# ML630Q466 register map
Vendor: LAPIS Semiconductor Co.,Ltd.; File version: 1.00
CPU: CM0PLUS r0p1, little endian, no MPU, no FPU, 2 interrupt priority bits
Registers are 32-bit, read-write, no defined reset value unless marked. A register's access mark holds for its fields unless they carry their own. Offsets are from the block's base; [hi:lo] are bit positions; {n}, {i} and the like mark numbered series.

## UART0
Base 0x41001000
0x00 UA0BUF ro — UART0 receive buffer
  [7:0] U0B
0x04 UA0CON — UART0 control register
  [7:0] U1B
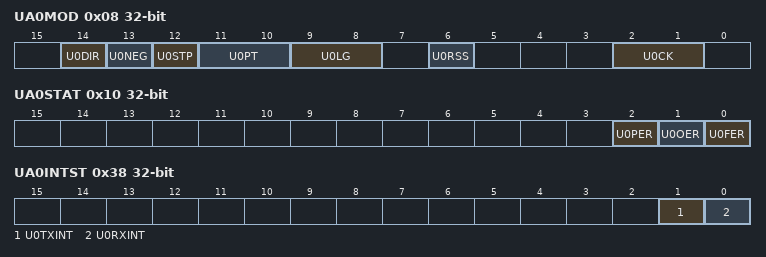
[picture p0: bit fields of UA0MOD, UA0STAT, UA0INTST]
0x08 UA0MOD — UART0 mode register
  [14] U0DIR, [13] U0NEG, [12] U0STP, [11:10] U0PT, [9:8] U0LG, [6] U0RSS, [2:1] U0CK
0x0C UA0BRT — UART0 baud rate register
  [13:0] U0BR
0x10 UA0STAT — UART0 receive status register
  [2] U0PER, [1] U0OER, [0] U0FER
0x20 UA1BUF — UART0 transmit buffer
  [7:0] U1B
0x24 UA1CON ro — UART0 transmit monitor register
  [0] U1EN
0x30 UA1STAT — UART0 transmit status register
  [3] U1FUL
0x38 UA0INTST — UART0 interrupt status register
  [1] U0TXINT, [0] U0RXINT

## UARTF0
Base 0x41001800
0x00 UAF0BUF — UARTF0 transmit/receive buffer
  [15:0] UF0B
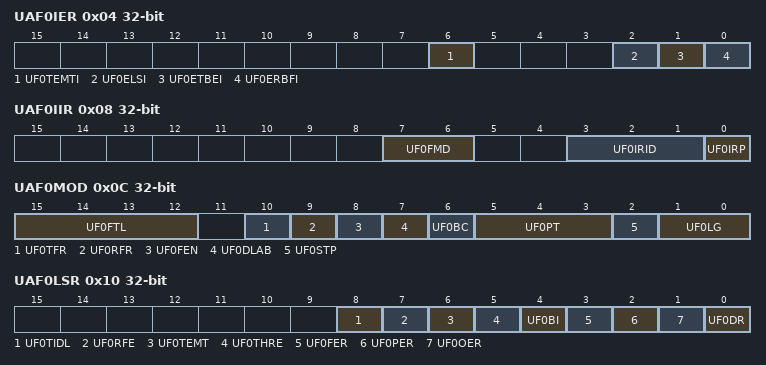
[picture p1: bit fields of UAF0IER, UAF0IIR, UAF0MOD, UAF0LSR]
0x04 UAF0IER — UARTF0 interrupt enable register
  [6] UF0TEMTI, [2] UF0ELSI, [1] UF0ETBEI, [0] UF0ERBFI
0x08 UAF0IIR ro — UARTF0 interrupt status register
  [7:6] UF0FMD, [3:1] UF0IRID, [0] UF0IRP
0x0C UAF0MOD — UARTF0 mode register
  [15:12] UF0FTL, [10] UF0TFR, [9] UF0RFR, [8] UF0FEN, [7] UF0DLAB, [6] UF0BC, [5:3] UF0PT, [2] UF0STP, [1:0] UF0LG
0x10 UAF0LSR ro — UARTF0 line status register
  [8] UF0TIDL, [7] UF0RFE, [6] UF0TEMT, [5] UF0THRE, [4] UF0BI, [3] UF0FER, [2] UF0PER, [1] UF0OER, [0] UF0DR
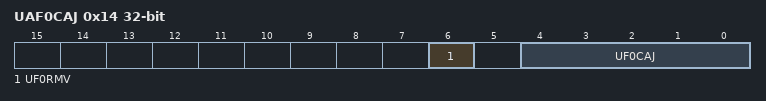
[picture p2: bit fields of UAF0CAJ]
0x14 UAF0CAJ — UARTF0 clock adjustment register
  [6] UF0RMV, [4:0] UF0CAJ

## I2C1
Base 0x41002000
0x00 I2C1RD ro — I2C bus 1 receive data register
  [7:0] I21R
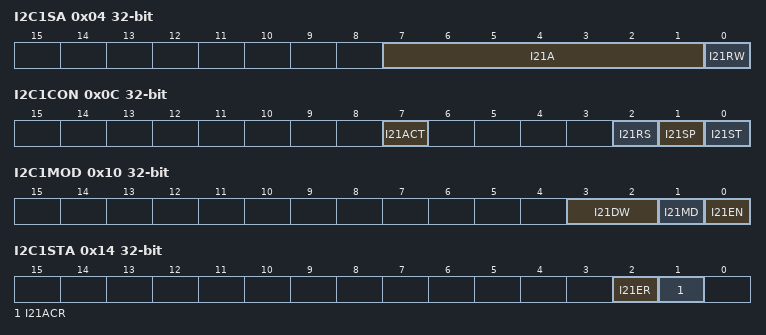
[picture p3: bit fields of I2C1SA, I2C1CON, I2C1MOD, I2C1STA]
0x04 I2C1SA — I2C bus 1 slave address register
  [7:1] I21A, [0] I21RW
0x08 I2C1TD — I2C bus 1 transmit data register
  [7:0] I21T
0x0C I2C1CON access per field — I2C bus 1 control register
  [7] I21ACT rw, [2] I21RS wo, [1] I21SP wo, [0] I21ST rw
0x10 I2C1MOD — I2C bus 1 mode register
  [3:2] I21DW, [1] I21MD, [0] I21EN
0x14 I2C1STA ro — I2C bus 1 status register
  [2] I21ER, [1] I21ACR

## I2CF0
Base 0x41002800
0x00 I2F0SAD — I2CF0 slave address register
  [10:1] I2F0SA
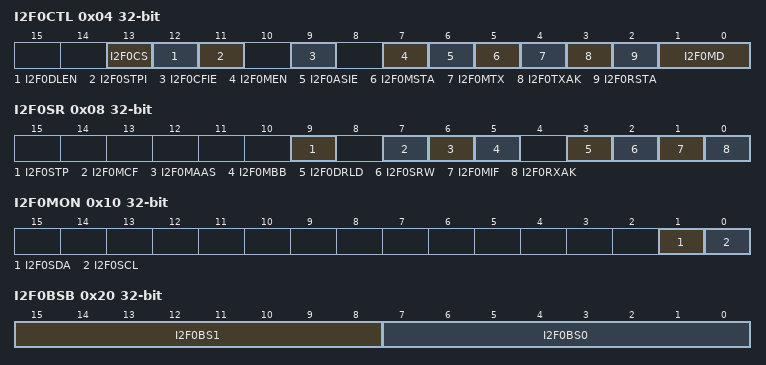
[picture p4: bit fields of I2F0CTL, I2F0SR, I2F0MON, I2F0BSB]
0x04 I2F0CTL — I2CF0 control register
  [13] I2F0CS, [12] I2F0DLEN, [11] I2F0STPI, [9] I2F0CFIE, [7] I2F0MEN, [6] I2F0ASIE, [5] I2F0MSTA, [4] I2F0MTX, [3] I2F0TXAK, [2] I2F0RSTA, [1:0] I2F0MD
0x08 I2F0SR — I2CF0 status register
  [9] I2F0STP, [7] I2F0MCF, [6] I2F0MAAS, [5] I2F0MBB, [3] I2F0DRLD, [2] I2F0SRW, [1] I2F0MIF, [0] I2F0RXAK
0x0C I2F0DR — I2CF0 data register
  [7:0] I2F0DA
0x10 I2F0MON ro — I2CF0 bus monitor register
  [1] I2F0SDA, [0] I2F0SCL
0x14 I2F0BC — I2CF0 bus transfer rate setup counter
  [6:0] I2F0BSC
0x18 I2F0MOD — I2CF0 mode register
  [0] I2F0BMEN
0x1C I2F0BSV — I2CF0 buffer mode slave address register
  [15:0] I2F0BA
0x20 I2F0BSB — I2CF0 buffer mode sub address register
  [15:8] I2F0BS1, [7:0] I2F0BS0
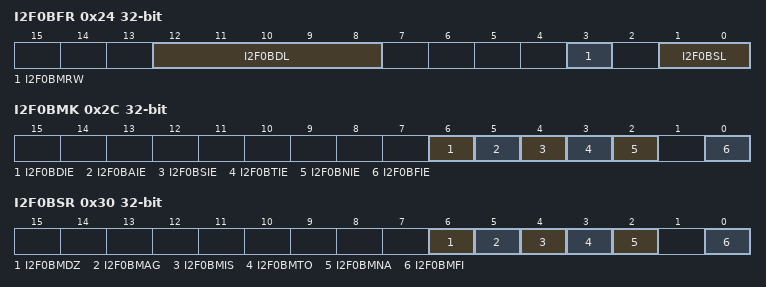
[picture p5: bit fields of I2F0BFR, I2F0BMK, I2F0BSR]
0x24 I2F0BFR — I2CF0 buffer mode format register
  [12:8] I2F0BDL, [3] I2F0BMRW, [1:0] I2F0BSL
0x28 I2F0BCT — I2CF0 buffer mode control register
  [0] I2F0BMST
0x2C I2F0BMK — I2CF0 buffer mode interrupt mask register
  [6] I2F0BDIE, [5] I2F0BAIE, [4] I2F0BSIE, [3] I2F0BTIE, [2] I2F0BNIE, [0] I2F0BFIE
0x30 I2F0BSR — I2CF0 buffer mode status register
  [6] I2F0BMDZ, [5] I2F0BMAG, [4] I2F0BMIS, [3] I2F0BMTO, [2] I2F0BMNA, [0] I2F0BMFI
0x34 I2F0BLV — I2CF0 buffer mode level register
  [4:0] I2F0BML
0x48 I2F0TMR — I2CF0 timer register
  [15:0] I2F0T
0x50 I2F0NF — I2CF0 input noise filter setting register
  [0] I2F0NFON

## USBDEV
Base 0x41004000
0x00 BMREQUESTTYPE ro — bmRequestType setup register
  [7:0] D
0x04 BREQUEST ro — bRequest setup register
  [7:0] D
0x08 WVALUELSB ro — wValueLSB setup register
  [7:0] D
0x0C WVALUEMSB ro — wValueMSB setup register
  [7:0] D
0x10 WINDEXLSB ro — wIndexLSB setup register
  [7:0] D
0x14 WINDEXMSB ro — wIndexMSB setup register
  [7:0] D
0x18 WLENGTHLSB ro — wLengthLSB setup register
  [7:0] D
0x1C WLENGTHMSB ro — wLengthMSB setup register
  [7:0] D
0x80 DVCADR — Device address register
  [6:0] D
0x84 INTSTAT1 ro — Interrupt status register 1
  [7:0] D
0x88 INTSTAT2 ro — Interrupt status register 2
  [4:0] D
0x90 INTENBL1 — Interrupt enable register 1
  [7:0] D
0x94 INTENBL2 — Interrupt enable register 2
  [4:0] D
0xB0 ISOMODESEL — Isochronous mode select register
  [5:4] D
0xB4 FRAMELSB ro — Frame number register LSB
  [7:0] D
0xB8 FRAMEMSB ro — Frame number register MSB
  [2:0] D
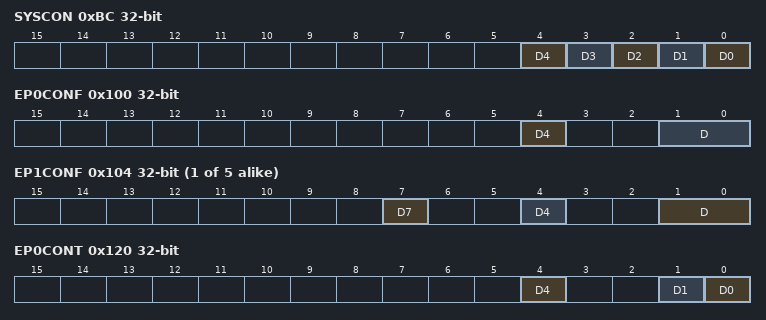
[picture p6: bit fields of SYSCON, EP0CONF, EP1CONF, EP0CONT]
0xBC SYSCON access per field — System control register
  [4] D4 wo, [3] D3 rw, [2] D2 rw, [1] D1 rw, [0] D0 wo
0xC0 POLSEL — Polarity select register
  [4] D
0xE8 OSCTEST — Oscillation test register
  [2:0] D
0xFC TXCLKCONT — Transmit clock control register
  [0] D
0x100 EP0CONF ro — EP0 configuration register
  [4] D4, [1:0] D
{0x100+4i} EP{i}CONF (i=1..5) — EP{i} configuration register
  [7] D7, [4] D4, [1:0] D
0x120 EP0CONT access per field — EP0 control register
  [4] D4 ro, [1] D1 ro, [0] D0 rw
{0x120+4i} EP{i}CONT (i=1..5) — EP{i} control register
  [2:0] D
0x140 EP0PLD — EP0 payload register
  [5:0] D
0x144 EP1PLD — EP1 payload register
  [6:0] D
0x148 EP2PLD — EP2 payload register
  [6:0] D
0x14C EP3PLD — EP3 payload register
  [5:0] D
0x150 EP4PLD — EP4 payload register
  [7:0] D
0x154 EP5PLD — EP5 payload register
  [7:0] D
0x160 EP0RXCNT ro — EP0 receive byte counter
  [5:0] D
0x164 EP1RXCNT ro — EP1 receive byte counter
  [6:0] D
0x168 EP2RXCNT ro — EP2 receive byte counter
  [6:0] D
0x16C EP3RXCNT ro — EP3 receive byte counter
  [5:0] D
0x170 EP4RXCNT ro — EP4 receive byte counter
  [7:0] D
0x174 EP5RXCNT ro — EP5 receive byte counter
  [7:0] D
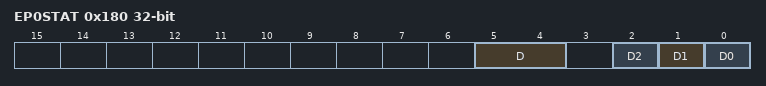
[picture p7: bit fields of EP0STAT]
0x180 EP0STAT — EP0 status register
  [5:4] D, [2] D2, [1] D1, [0] D0
{0x180+4i} EP{i}STAT (i=1..5) — EP{i} status register
  [1:0] D
0x1C0 EP0TXFIFO wo — EP0 transmit FIFO
  [31:0] D
0x1E0 EP0RXFIFO ro — EP0 receive FIFO
  [31:0] D
{0x1E0+4i} EP{i}FIFO (i=1..5) — EP{i} transmit/receive FIFO
  [31:0] D
